# COMPUTE_CLUSTER0_MSMC_CFGS0 register map
Vendor: Texas Instruments
Peripheral module from a debugger description file (folder am65x).
Registers are 64-bit, access per field, reset 0x0 unless marked. A register's access mark holds for its fields unless they carry their own. Offsets are as the file gives them; lines under a group give offsets from that group; [hi:lo] are bit positions; {n}, {i} and the like mark numbered series; 'fields as' and 'values as' point back to an identical list; <NAME> marks a mode.

## COMPUTE_CLUSTER0_MSMC_CFGS0
0x00 MSMC_PID ro — Peripheral ID Register.
  [31:0] REVISION — PID Revision
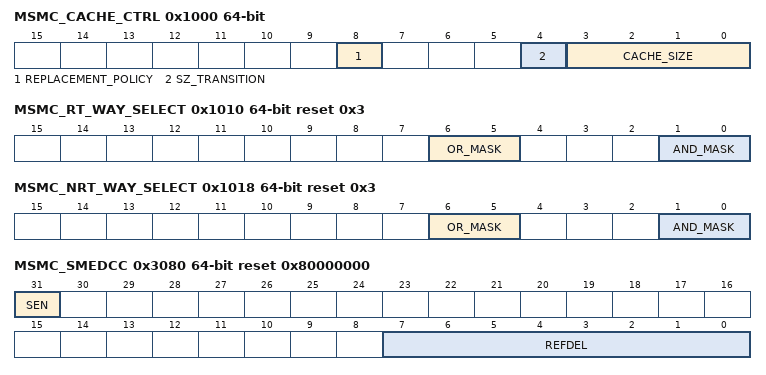
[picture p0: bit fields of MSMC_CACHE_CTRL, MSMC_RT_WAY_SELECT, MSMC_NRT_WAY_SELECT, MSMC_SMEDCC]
0x1000 MSMC_CACHE_CTRL — Cache Control Register.
  [8] REPLACEMENT_POLICY rw
  [4] SZ_TRANSITION ro — Cache Size Change in Progress
  [3:0] CACHE_SIZE rw — Cache Size Control
0x1010 MSMC_RT_WAY_SELECT reset 0x3 — Real Time Way Select.
  [6:5] OR_MASK rw — OR mask for way-select
  [1:0] AND_MASK rw — AND mask for way-select
0x1018 MSMC_NRT_WAY_SELECT reset 0x3 — Non Real Time Way Select.
  fields as MSMC_RT_WAY_SELECT
0x2048 MSMC_COHCTRL — Coherence Control Register.
  [0] BCM rw — Broadcast Mode
0x3080 MSMC_SMEDCC reset 0x80000000 — Scrub Rate Register.
  [31] SEN rw — Scrub Engine Enable
  [7:0] REFDEL rw — Number of Clock Cycles Between Scrubs
0x5000 MSMC_SMESTAT ro — Interrupt Enabled Status register. ANDed value of MSMC_SMIRSTAT and MSMC_SMIESTAT.
  [0] NULL_SLV — Null slave error is enabled and pending
0x5008 MSMC_SMIRSTAT ro — Interrupt raw status register.
  [0] NULL_SLV — Null slave error flagged
0x5008 MSMC_SMIRWS — set interrupt raw status register.
  [0] NULL_SLV wo — Set software null slave error
0x5010 MSMC_SMIRC — Interrupt clear register.
  [0] NULL_SLV wo — Clear null slave error flag
0x5018 MSMC_SMIESTAT ro — Interrupt raw status register.
  [0] NULL_SLV — Null slave error interrupt is enabled
0x5018 MSMC_SMIEWS — set interrupt raw status register.
  [0] NULL_SLV wo — Enable null slave error
0x5020 MSMC_SMIEC — Interrupt clear register.
  [0] NULL_SLV wo — clear null slave error interrupt enable
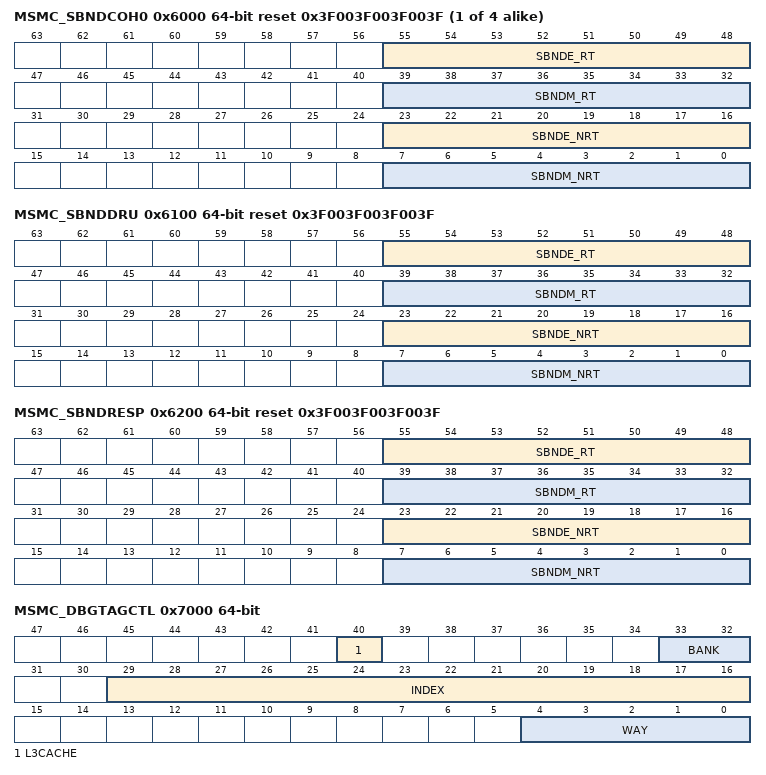
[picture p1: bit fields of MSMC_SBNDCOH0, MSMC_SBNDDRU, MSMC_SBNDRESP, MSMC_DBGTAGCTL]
{0x6000+8i} MSMC_SBNDCOH{i} reset 0x3F003F003F003F (i=0..3) — Starvation Bound for Coherent Port {i}.
  [55:48] SBNDE_RT rw — Starvation Bound for Real-Time External Memory
  [39:32] SBNDM_RT rw — Starvation Bound for Real-Time On-Chip Memory
  [23:16] SBNDE_NRT rw — Starvation Bound for Non-Real-Time External Memory
  [7:0] SBNDM_NRT rw — Starvation Bound for Non-Real-Time On-Chip Memory
0x6100 MSMC_SBNDDRU reset 0x3F003F003F003F — Starvation Bound for Data Routing Unit.
  fields as MSMC_SBNDCOH0
0x6200 MSMC_SBNDRESP reset 0x3F003F003F003F — Starvation Bound for Read Response.
  fields as MSMC_SBNDCOH0
0x7000 MSMC_DBGTAGCTL — Debug Tag View Control.
  [40] L3CACHE rw — Level 3 Cache Tag Select
  [33:32] BANK rw — Physical Bank Select
  [29:16] INDEX rw — Index Select
  [4:0] WAY rw — Way Select
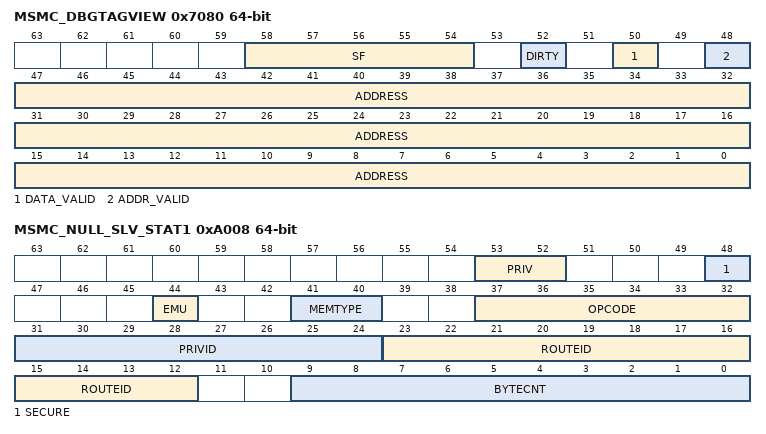
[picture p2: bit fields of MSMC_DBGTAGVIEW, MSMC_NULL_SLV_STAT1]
0x7080 MSMC_DBGTAGVIEW ro — Debug Tag View Read.
  [58:54] SF — Snoop Filter
  [52] DIRTY
  [50] DATA_VALID
  [48] ADDR_VALID — Address Valid
  [47:0] ADDRESS — Tag Address
0xA000 MSMC_NULL_SLV_STAT0 ro — Null Slave Status 0.
  [63:0] ADDR — Address
0xA008 MSMC_NULL_SLV_STAT1 ro — Null Slave Status 1.
  [53:52] PRIV — Privilege
  [48] SECURE
  [44] EMU — Emulation
  [41:40] MEMTYPE — Memory Type
  [37:32] OPCODE
  [31:24] PRIVID
  [23:12] ROUTEID
  [9:0] BYTECNT — Byte Count
0xA018 MSMC_NULL_SLV_CNT — Null Slave Error Count.
  [7:0] COUNT rw
